# YTM32B1ME1 register map
Vendor: YTMicro; File version: 1.0
CPU: CM33 r0p4, little endian, MPU, FPU, 2 interrupt priority bits
Registers are 32-bit, read-write, reset 0x0 unless marked. A register's access mark holds for its fields unless they carry their own. Offsets are from the block's base; [hi:lo] are bit positions; {n}, {i} and the like mark numbered series.

## SPI0 — Serial Port Interface
Base 0x400A8000; register names take the prefix SPI0_
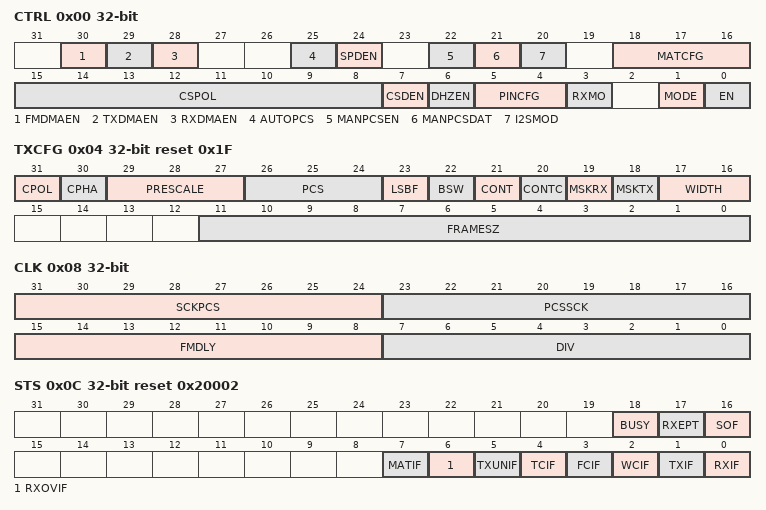
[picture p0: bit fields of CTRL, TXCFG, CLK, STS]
0x00 CTRL
  [30] FMDMAEN — Control bit to control weather DMA request generated after one frame transmit/receive done
    0=DMA request disabled; 1=DMA request enabled
  [29] TXDMAEN — TX DATA request DMA enable when TX fifo less than watermark or buff empty
    0=DMA request disabled; 1=DMA request enabled
  [28] RXDMAEN — RX DATA request DMA enable when RX fifo great than watermark or buff full
    0=DMA request disabled; 1=DMA request enabled
  [25] AUTOPCS — When SPI in slave mode, setting this bit will cause SPI slave to automatically generate an internal PCS signal when TXCFG[CPHA]=1
    0=SPI slave use PCS pin directly; 1=SPI slave will regenerate internal PCS signal
  [24] SPDEN — Setting this bit will enable sample delay logic before data input under master mode.
    0=SPI sample data on SCK edge; 1=SPI sample data on delayed SCK edge
  [22] MANPCSEN — Setting this bit will enable software to manually set PCS value in SPI slave mode. ote{ MANPCSEN and MANPCSDAT enables the slave configured SPI to work without an input PCS signal.}
    0=PCS of SPI slave mode is input from pin; 1=PCS of SPI slave mode can be manually set by MANPCSDAT register
  [21] MANPCSDAT — When SPI works in slave mode and MANPCSEN register value is 1, software write MANPCSDAT from 0 to 1 to start receive data. MANPCSDAT is ignored if SPI works in master mode or if MANPCSEN value is 0.
    0=PCS value is set to 0 when MANPCSEN is 1; 1=PCS value is set to 1 when MANPCSEN is 1
  [20] I2SMOD — Setting this bit will enable Phillips standard I2S transfer.
    0=Disable I2S mode; 1=Enable I2S mode. Please set TXCFG[CPOL] = 0, TXCFG[CPHA]=0 and TXCFG[CONT]=1 in this mode.
  [18:16] MATCFG — SPI match feature configuration
    0=Match disabled; 2=First data match MATCH0 or MATCH1; 3=Any data match MATCH0 or MATCH1; 4=First data match MATCH0 and second data match MATCH1; 5=Any data match MATCH0 and next data match MATCH1; 6=First data bit AND with MATCH1 match MATCH0 AND MATCH1; 7=Any data bit AND with MATCH1 match MATCH0 AND MATCH1
  [15:8] CSPOL — Pin selection polarity selection of pcs pin.
    0=set PCS[n] to active low; 1=set PCS[n] to active high
  [7] CSDEN — Setting this bit will change SPI PCS[3:2] pin as data line to support 4 data lines transfer
    0=PCS pin works as normal chip selection function; 1=SPI works in half_duplex 4 data lines mode and PCS[3:2] is DATA[3:2]
  [6] DHZEN — Setting this bit will set output data line to high z when chip select is negated
    0=SPI data output line keeps at last value when chip select is negated; 1=SPI data output line in high z mode when chip select is negated
  [5:4] PINCFG — Control the data input source and data output target. Please refer to \hyperref[pin-configuration]{Pin Configuration} chapter for more details.
  [3] RXMO — When this bit is set and TXCFG[MSKRX]=0, SPI stores the received data into RX FIFO only when match event occurs.
    0=SPI will store all received data; 1=SPI will only store data after data matched
  [1] MODE — SPI Master/slave mode selection
    0=SPI slave mode; 1=SPI master mode
  [0] EN — Write to this field will enable/disable SPI module ewline Read this field will reflect current SPI module state ewline ote{This bit only update when SPI logic is enabled or disabled successfully}
    0=SPI module is disabled; 1=SPI module is enabled
0x04 TXCFG reset 0x1F — Any data written to TXCFG will be push to TX FIFO, TXCFG will only support 32 bit access, and the configuration in TXCFG will only affect following Data transmissions. ewline ote{TXCFG should only update when SPI is IDLE} ote{Read TXCFG should read twice check or read when SPI TX FIFO empty}
  [31] CPOL — Clock polarity of following data transfer. This field can't be changed when CONTC = 1.
    0=Clock idles low, leading edge is rising, trailing edge is falling; 1=Clock idles high, leading edge is falling, trailing edge is rising
  [30] CPHA — Clock phase fo following data transfer. This field can't be changed when CONTC = 1.
    0=Data captured on clock leading edge, Data changed on clock trailing edge; 1=Data captured on clock trailing edge, Data changed on clock leading edge
  [29:27] PRESCALE — Clock prescaler of following SPI clock. This field can't be changed when CONTC = 1.
    0=SPI clock divided by 1; 1=SPI clock divided by 2; 2=SPI clock divided by 4; 3=SPI clock divided by 8; 4=SPI clock divided by 16; 5=SPI clock divided by 32; 6=SPI clock divided by 64; 7=SPI clock divided by 128
  [26:24] PCS — Changing this field will change following peripheral selection. PCS can only be configured to 0 or 1 in 4-data line half-duplex mode. This field can't be changed when CONTC = 1.
    {v}=Peripheral {v} selected (v=0..7)
  [23] LSBF — Setting this bit will change following data transfer shift order.
    0=MSB is shifted first in data transfer; 1=LSB is shifted first in data transfer
  [22] BSW — Setting this bit will change 32-bit data byte order, this bit controls both TX and RX FIFO
    0=Byte swap mode not enabled; 1=Byte[3] swap with Byte[0], Byte[2] swap with Byte[1]
  [21] CONT — In master mode, continuous transfer will keep PCS selected, no space will be inserted between data frame.
    0=Continuous transfer mode is disabled; 1=Continuous transfer mode is enabled
  [20] CONTC — Setting this bit will allow insert command during continuous transfer
    0=Continuous command mode is disabled; 1=Continuous command mode is enabled
  [19] MSKRX — Setting this bit will disable writing received data to RX FIFO
    0=Received data will write to RX FIFO; 1=Received data won't write to RX FIFO
  [18] MSKTX — In master mode, setting this bit will SPI start a new transfer, SPI data out will be tristated ewline This bit is used to receive data from slave in half-duplex mode. ewline ote{This bit is cleared by hardware when data transfer ends.}
    0=Normal data transfer; 1=Mask TX data and start a data transfer
  [17:16] WIDTH — Changing this field allows SPI working in 2 line or 4 line mode. ewline Please refer to chpater \hyperref[pin-configuration]{Pin Configuration} for details of PIN connection and CTRL[PINCFG] value in 2 line or 4 line mode. ewline ote{MSKTX or MSKRX must be set to let SPI working in half_duplex mode; ewline DHZEN must be set to 1 when SPI works in 2 line or 4 line mode. }
    0=1 data line, normal mode; 1=2 data line \{SIN, SOUT\}, half-duplex mode; 2=4 data line\{[PCS[3:2], SIN, SOUT\}, half-duplex mode
  [11:0] FRAMESZ — One frame include FRAMESZ + 1 bits
0x08 CLK
  [31:24] SCKPCS — Control the delay from last SCK to the PCS negation, only valid in SPI master mode ewline The delay is SCKPCS + 1 divided SPI clock divided by TXCFG[PRESCALE] field
  [23:16] PCSSCK — CS to SCK delay
  [15:8] FMDLY — Control SCK delay between frames in continuous mode or the time of PCS negation, only valid in master mode \begin{itemize}[] \item Delay between frames in continuous mode is FMDLY + 1 divided SPI clock divided by TXCFG[PRESCALE] field \item PCS negation time is FMDLY + 1 divided SPI clock divided by TXCFG[PRESCALE] field \vspace*{-\baselineskip} \end{itemize}
  [7:0] DIV — SPI clock period is DIV + 2 divided SPI clock divided by TXCFG[PRESCALE] field
0x0C STS reset 0x20002
  [18] BUSY ro — SPI module is transmitting or receiving data
    0=SPI module is idle; 1=SPI module is busy
  [17] RXEPT
    0=SPI RX FIFO is not empty; 1=SPI RX FIFO is empty
  [16] SOF — Indicates SPI received first data frame
    0=Received data after first frame or idle; 1=Received first frame data
  [7] MATIF — Indicates SPI received data matched data match configuration
    0=Received data not matched; 1=Received data matched
  [6] RXOVIF — Indicates SPI RX FIFO is overflowed
    0=RX FIFO is not overflowed; 1=RX FIFO is overflowed
  [5] TXUNIF — Indicates SPI TX FIFO is underflow
    0=TX FIFO is not underflow; 1=TX FIFO is underflow
  [4] TCIF — Indicates SPI has finished data transfer and return to idle
    0=All data transfer not completed; 1=All data transfer completed
  [3] FCIF — Indicates SPI has finished one frame data transfer
    0=One frame data transfer not completed; 1=One frame data transfer completed
  [2] WCIF — Indicates SPI has finished one word data transfer
    0=One word data transfer not completed; 1=One word data transfer completed
  [1] TXIF ro — Indicates words in TX FIFO is equal or less than TX FIFO watermark setting
    0=Word in TX FIFO is greater than watermark; 1=Word in TX FIFO is equal or less than watermark, request to write new data
  [0] RXIF ro — Indicates words in RX FIFO is greater than RX FIFO watermark setting
    0=Word in RX FIFO is equal or less than watermark; 1=Word in RX FIFO is greater than watermark, should read data register
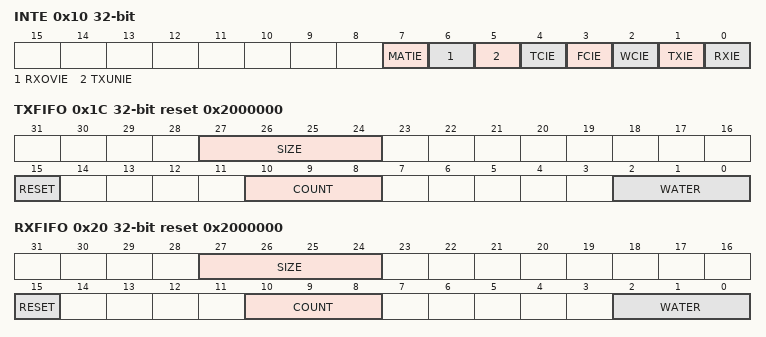
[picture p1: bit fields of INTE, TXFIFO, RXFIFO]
0x10 INTE
  [all] fields
    0=Interrupt disabled; 1=Interrupt enabled
  [7] MATIE
  [6] RXOVIE
  [5] TXUNIE
  [4] TCIE
  [3] FCIE
  [2] WCIE
  [1] TXIE
  [0] RXIE
0x14 MATCH0
0x18 MATCH1
0x1C TXFIFO reset 0x2000000
  [27:24] SIZE ro — Available TX FIFO Size is 2^SIZE words
  [15] RESET wo — Reset TX FIFO address pointer
  [10:8] COUNT ro — SPI TX FIFO current data count
  [2:0] WATER — TXIF set when words count in TX FIFO equal or less than watermark
0x20 RXFIFO reset 0x2000000
  [27:24] SIZE ro — Available RX FIFO Size is 2^SIZE words
  [15] RESET wo — Reset SPI RX FIFO address pointer
  [10:8] COUNT — SPI RX FIFO current data count
  [2:0] WATER — RXIF set when words count in RX FIFO greater than watermark
0x24 DATA
  [31:0] DATA — Read DATA will return SPI received data in RX FIFO ewline Write DATA will push new data into TX FIFO ewline ote{This register could only access in word.}

## SPI1 — Serial Port Interface
Base 0x400AC000; register names take the prefix SPI1_
Registers as SPI0.

## SPI2 — Serial Port Interface
Base 0x400B0000; register names take the prefix SPI2_
Registers as SPI0.

## SPI3 — Serial Port Interface
Base 0x400B4000; register names take the prefix SPI3_
Registers as SPI0.

## SPI4 — Serial Port Interface
Base 0x400B8000; register names take the prefix SPI4_
Registers as SPI0.

## SPI5 — Serial Port Interface
Base 0x400BC000; register names take the prefix SPI5_
Registers as SPI0.
